# MTIF_367.0 register map
Vendor: Texas Instruments
Peripheral module from a debugger description file (folder msp430).
Registers are 16-bit, read-write, no defined reset value unless marked. A register's access mark holds for its fields unless they carry their own. Offsets are as the file gives them; lines under a group give offsets from that group; [hi:lo] are bit positions; {n}, {i} and the like mark numbered series; 'fields as' and 'values as' point back to an identical list; <NAME> marks a mode.

## MTIF
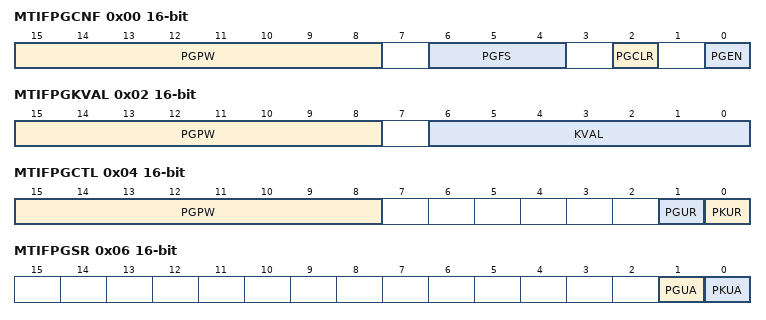
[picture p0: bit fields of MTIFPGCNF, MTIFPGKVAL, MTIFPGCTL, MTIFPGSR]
0x00 MTIFPGCNF — Pulse Generator Configuration Register
  [15:8] PGPW — PG password. Always reads as 0x69. Must be written as 0x5A for register changes to be effective. This password differs from the pin configuration and pulse counter passwords.
  [6:4] PGFS — PG pulse grid frequency select. This value determines at which time grid pulses are generated. The pulse generator frame frequency is an 1/256th of this (PGEN has to be one to perform a change).
    0=Pulse grid frequency is set to 8 Hz (nominal); 1=Pulse grid frequency is set to 16 Hz (nominal); 2=Pulse grid frequency is set to 32 Hz (nominal); 3=Pulse grid frequency is set to 64 Hz (nominal); 4=Pulse grid frequency is set to 128 Hz (nominal); 5=Pulse grid frequency is set to 256 Hz (nominal); 6=Pulse grid frequency is set to 512 Hz (nominal); 7=Pulse grid frequency is set to 1024 Hz (nominal) default
  [2] PGCLR — PG pulse counter clear. This bit allows to clear the pulse generator (PGEN has to be set to one to perform a clear). Note!: A clear request is being latched and released after the clear is executed. PCEN =0 and LFXTOFF=1 will prevent that. The clear occurs then after the clock is reenabled. This bit is for triggering only; it's state cannot be read back
  [0] PGEN — PG sub module enable. This bit enables the PG sub module when set to one
0x02 MTIFPGKVAL — Pulse Generator Value Register
  [15:8] PGPW — PG password. Always reads as 0x69. Must be written as 0x5A for register changes to be effective. This password differs from the pin configuration and pulse counter passwords.
  [6:0] KVAL — Pulse Count Number. This register value determines how many pulses are generated withing 256 periods of the pulse grid frequency(with password protection as in PGCNF). PGEN has to be one to perform a change.
0x04 MTIFPGCTL — Pulse Generator Control Register
  [15:8] PGPW — PG password. Always reads as 0x69. Must be written as 0x5A for register changes to be effective. This password differs from the pin configuration and pulse counter passwords.
  [1] PGUR — Pulse Grid Frequency Update Request (with password protection as in PGCNF). The update of PGFS occurs during the frequency grid slot 0xff (e.g. in the last 4ms of an second with an pulse grid frequency of 256Hz)
  [0] PKUR — Pulse K-Count Update Request (with password protection as in PGCNF). The update of KVAL occurs during the frequency grid slot 0xff (e.g. in the last 4ms of a second with a pulse grid frequency of 256Hz)
0x06 MTIFPGSR — Pulse Generator Status Register
  [1] PGUA — Pulse Grid Frequency Update Acknowledge. This acknowledges a PGUR directly after the PGFS has been updated.
  [0] PKUA — Pulse K-Count Update Acknowledge. This acknowledges a PCUR directly after the K-values has been updated.
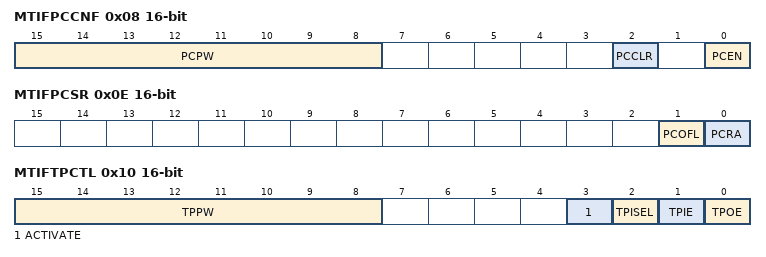
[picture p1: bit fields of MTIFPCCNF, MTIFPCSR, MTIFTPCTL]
0x08 MTIFPCCNF — Pulse Counter Configuration Register
  [15:8] PCPW — Pulse counter password. Always reads as 0x96. Must be written as 0xA5 for register changes to be effective. This password differs from the pin configuration and pulse generator passwords
  [2] PCCLR — Pulse counter clear. This bit allows to clear the pulse counter when set to one (PCEN has to be one to perform a clear). Note!: A clear request is being latched and released after the clear is executed. LFXTOFF=1 and PCEN=0 will prevent that. The clear occurs then after the clock is reenabled. This bit is for triggering only; it's state cannot be read back
  [0] PCEN — PC sub module enable. This bit enables the PC sub module when set to one
0x0A MTIFPCR access not given — Pulse Counter Value Register
0x0C MTIFPCCTL — Pulse Counter Control Register
  [0] PCRR — Pulse Counter Read Request. Set this to request an update of PCR read register from the actual counter.
0x0E MTIFPCSR — Pulse Counter Status Register
  [1] PCOFL — Pulse counter overflow. This bit indicates an overflow of the pulse counter when its value changes since the last read request procedure. It is basically the 17th bit of the counter
  [0] PCRA — Pulse counter read acknowledge. This acknowledges the update of the PCR register as response to the PCRR read request. Note!: A read request is being latched. LFXTOFF=1 and PCEN=0 will prevent that.The read will then be performed and acknowledged after the clock is reenabled.
0x10 MTIFTPCTL — Measurement Test Port Control Register
  [15:8] TPPW — Test port password. Always reads as 0x0F. Must be written as 0xC3 for register changes to be effective.This password differs from the pulse generator and pulse counter passwords
  [3] ACTIVATE — Test port terminal enable activation. This value determines if the testport output is enabled solely by software or by software and hardware.
    0=The test port output is enabled solely by TPOE (enabled if TPOE=1); 1=The testport output requires both TPOE to be high and the MTPE pin to be high to be enabled
  [2] TPISEL — Test port input select for pulse counter. This value determines the source for the pulse counter.
    0=The pulse generator is used as input; 1=The test port input terminal is selected as input
  [1] TPIE — Test port input enable. This bit allows to enable the test input port
  [0] TPOE — Test port output enable. This bit allows to enable the test pulse output when set to one
